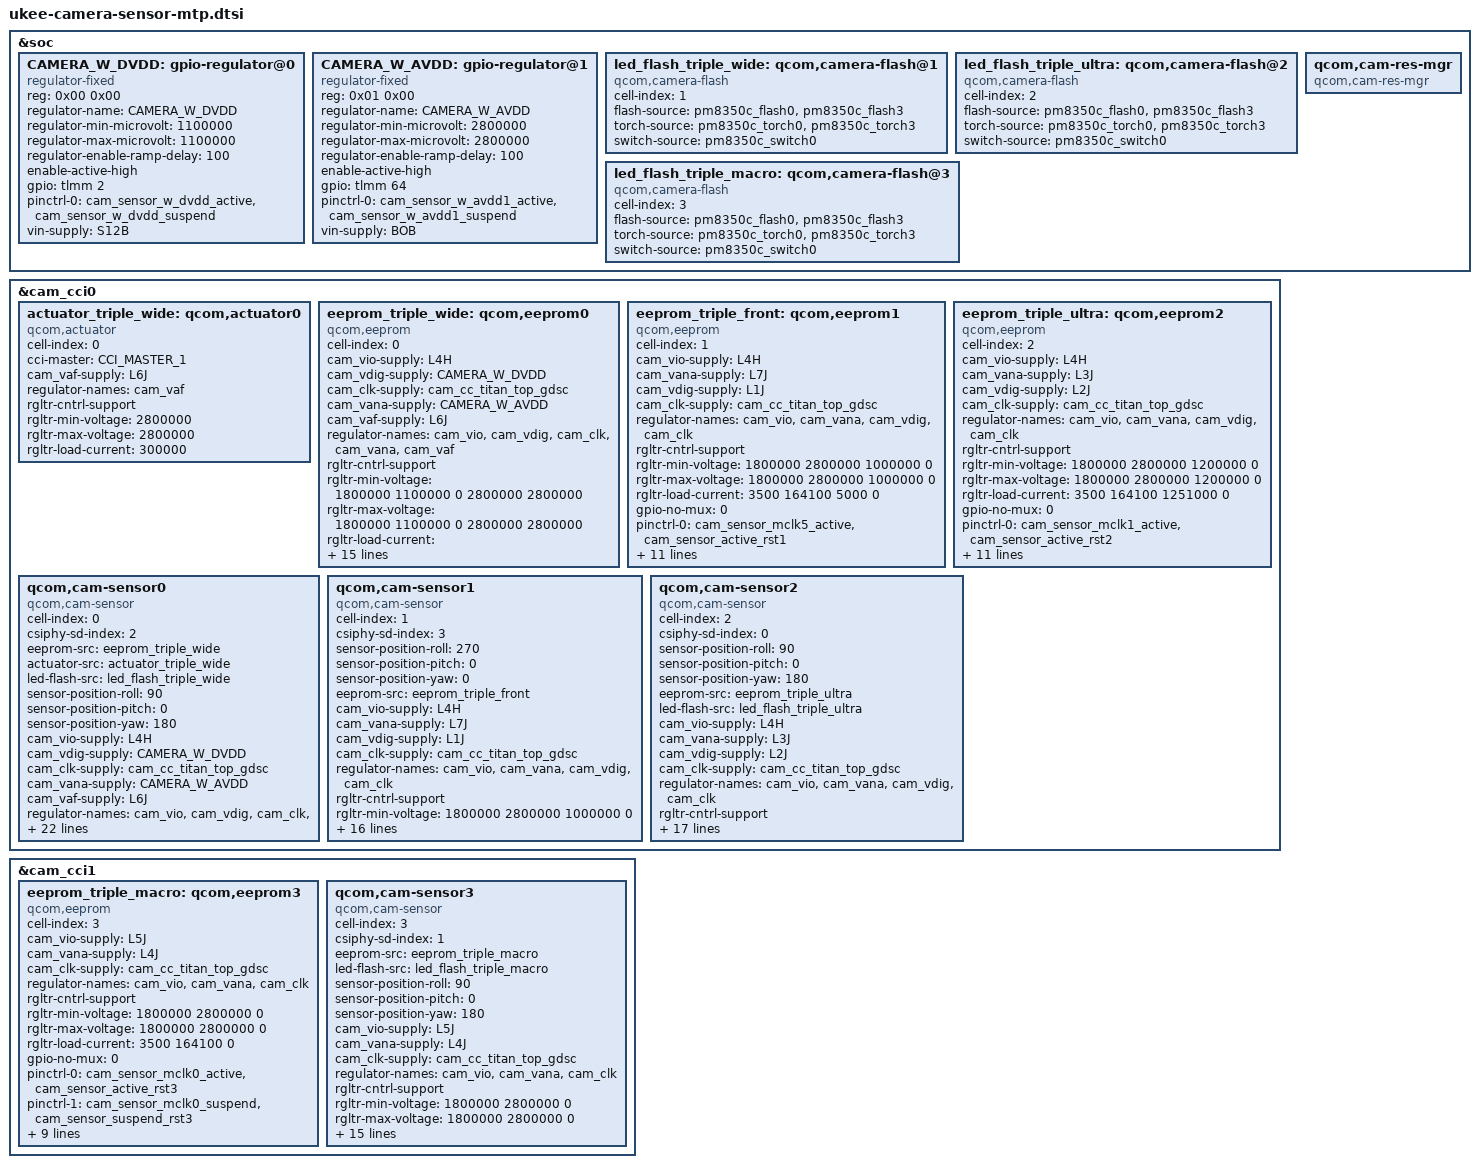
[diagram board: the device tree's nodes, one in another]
#include <dt-bindings/clock/qcom,camcc-waipio.h>
#include <dt-bindings/msm-camera.h>

&soc {
	CAMERA_W_DVDD: gpio-regulator@0 {
		compatible = "regulator-fixed";
		reg = <0x00 0x00>;
		regulator-name = "CAMERA_W_DVDD";
		regulator-min-microvolt = <1100000>;
		regulator-max-microvolt = <1100000>;
		regulator-enable-ramp-delay = <100>;
		enable-active-high;
		gpio = <&tlmm 2 0>;
		pinctrl-names = "default", "sleep";
		pinctrl-0 = <&cam_sensor_w_dvdd_active
			&cam_sensor_w_dvdd_suspend>;
		vin-supply = <&S12B>;
	};

	CAMERA_W_AVDD: gpio-regulator@1 {
		compatible = "regulator-fixed";
		reg = <0x01 0x00>;
		regulator-name = "CAMERA_W_AVDD";
		regulator-min-microvolt = <2800000>;
		regulator-max-microvolt = <2800000>;
		regulator-enable-ramp-delay = <100>;
		enable-active-high;
		gpio = <&tlmm 64 0>;
		pinctrl-names = "default", "sleep";
		pinctrl-0 = <&cam_sensor_w_avdd1_active
			&cam_sensor_w_avdd1_suspend>;
		vin-supply = <&BOB>;
	};

	led_flash_triple_wide: qcom,camera-flash@1 {
		cell-index = <1>;
		compatible = "qcom,camera-flash";
		flash-source = <&pm8350c_flash0 &pm8350c_flash3>;
		torch-source = <&pm8350c_torch0 &pm8350c_torch3>;
		switch-source = <&pm8350c_switch0>;
		status = "ok";
	};

	led_flash_triple_ultra: qcom,camera-flash@2 {
		cell-index = <2>;
		compatible = "qcom,camera-flash";
		flash-source = <&pm8350c_flash0 &pm8350c_flash3>;
		torch-source = <&pm8350c_torch0 &pm8350c_torch3>;
		switch-source = <&pm8350c_switch0>;
		status = "ok";
	};

	led_flash_triple_macro: qcom,camera-flash@3 {
		cell-index = <3>;
		compatible = "qcom,camera-flash";
		flash-source = <&pm8350c_flash0 &pm8350c_flash3>;
		torch-source = <&pm8350c_torch0 &pm8350c_torch3>;
		switch-source = <&pm8350c_switch0>;
		status = "ok";
	};

	qcom,cam-res-mgr {
		compatible = "qcom,cam-res-mgr";
		status = "ok";
	};
};

&cam_cci0 {
	actuator_triple_wide: qcom,actuator0 {
		cell-index = <0>;
		compatible = "qcom,actuator";
		cci-master = <CCI_MASTER_1>;
		cam_vaf-supply = <&L6J>;
		regulator-names = "cam_vaf";
		rgltr-cntrl-support;
		rgltr-min-voltage = <2800000>;
		rgltr-max-voltage = <2800000>;
		rgltr-load-current = <300000>;
		status = "ok";
	};

	eeprom_triple_wide: qcom,eeprom0 {
		cell-index = <0>;
		compatible = "qcom,eeprom";
		cam_vio-supply = <&L4H>;
		cam_vdig-supply = <&CAMERA_W_DVDD>;
		cam_clk-supply = <&cam_cc_titan_top_gdsc>;
		cam_vana-supply = <&CAMERA_W_AVDD>;
		cam_vaf-supply = <&L6J>;
		regulator-names = "cam_vio", "cam_vdig",
			"cam_clk", "cam_vana", "cam_vaf";
		rgltr-cntrl-support;
		rgltr-min-voltage = <1800000 1100000 0 2800000 2800000>;
		rgltr-max-voltage = <1800000 1100000 0 2800000 2800000>;
		rgltr-load-current = <3500 1251000 0 164100 300000>;
		gpio-no-mux = <0>;
		pinctrl-names = "cam_default", "cam_suspend";
		pinctrl-0 = <&cam_sensor_mclk2_active
			&cam_sensor_active_rst0>;
		pinctrl-1 = <&cam_sensor_mclk2_suspend
			&cam_sensor_suspend_rst0>;
		gpios = <&tlmm 102 0>,
			<&tlmm 126 0>;
		gpio-reset = <1>;
		gpio-req-tbl-num = <0 1>;
		gpio-req-tbl-flags = <1 0>;
		gpio-req-tbl-label = "CAMIF_MCLK2",
					"CAM_RESET0";
		cci-master = <CCI_MASTER_1>;
		clocks = <&clock_camcc CAM_CC_MCLK2_CLK>;
		clock-names = "cam_clk";
		clock-cntl-level = "nominal";
		clock-rates = <19200000>;
		status = "ok";
	};

	eeprom_triple_front: qcom,eeprom1 {
		cell-index = <1>;
		compatible = "qcom,eeprom";
		cam_vio-supply = <&L4H>;
		cam_vana-supply = <&L7J>;
		cam_vdig-supply = <&L1J>;
		cam_clk-supply = <&cam_cc_titan_top_gdsc>;
		regulator-names = "cam_vio", "cam_vana", "cam_vdig",
			"cam_clk";
		rgltr-cntrl-support;
		rgltr-min-voltage = <1800000 2800000 1000000 0>;
		rgltr-max-voltage = <1800000 2800000 1000000 0>;
		rgltr-load-current = <3500 164100 5000 0>;
		gpio-no-mux = <0>;
		pinctrl-names = "cam_default", "cam_suspend";
		pinctrl-0 = <&cam_sensor_mclk5_active
			&cam_sensor_active_rst1>;
		pinctrl-1 = <&cam_sensor_mclk5_suspend
			&cam_sensor_suspend_rst1>;
		gpios = <&tlmm 105 0>,
			<&tlmm 127 0>;
		gpio-reset = <1>;
		gpio-req-tbl-num = <0 1>;
		gpio-req-tbl-flags = <1 0>;
		gpio-req-tbl-label = "CAMIF_MCLK5",
					"CAM_RESET1";
		cci-master = <CCI_MASTER_0>;
		clocks = <&clock_camcc CAM_CC_MCLK5_CLK>;
		clock-names = "cam_clk";
		clock-cntl-level = "nominal";
		clock-rates = <19200000>;
		status = "ok";
	};

	eeprom_triple_ultra: qcom,eeprom2 {
		cell-index = <2>;
		compatible = "qcom,eeprom";
		cam_vio-supply = <&L4H>;
		cam_vana-supply = <&L3J>;
		cam_vdig-supply = <&L2J>;
		cam_clk-supply = <&cam_cc_titan_top_gdsc>;
		regulator-names = "cam_vio", "cam_vana", "cam_vdig",
			"cam_clk";
		rgltr-cntrl-support;
		rgltr-min-voltage = <1800000 2800000 1200000 0>;
		rgltr-max-voltage = <1800000 2800000 1200000 0>;
		rgltr-load-current = <3500 164100 1251000 0>;
		gpio-no-mux = <0>;
		pinctrl-names = "cam_default", "cam_suspend";
		pinctrl-0 = <&cam_sensor_mclk1_active
				 &cam_sensor_active_rst2>;
		pinctrl-1 = <&cam_sensor_mclk1_suspend
				 &cam_sensor_suspend_rst2>;
		gpios = <&tlmm 101 0>,
			<&tlmm 24 0>;
		gpio-reset = <1>;
		gpio-req-tbl-num = <0 1>;
		gpio-req-tbl-flags = <1 0>;
		gpio-req-tbl-label = "CAMIF_MCLK1",
					"CAM_RESET2";
		cci-master = <CCI_MASTER_0>;
		clocks = <&clock_camcc CAM_CC_MCLK1_CLK>;
		clock-names = "cam_clk";
		clock-cntl-level = "nominal";
		clock-rates = <19200000>;
		status = "ok";
	};

	qcom,cam-sensor0 {
		cell-index = <0>;
		compatible = "qcom,cam-sensor";
		csiphy-sd-index = <2>;
		eeprom-src = <&eeprom_triple_wide>;
		actuator-src = <&actuator_triple_wide>;
		led-flash-src = <&led_flash_triple_wide>;
		sensor-position-roll = <90>;
		sensor-position-pitch = <0>;
		sensor-position-yaw = <180>;
		cam_vio-supply = <&L4H>;
		cam_vdig-supply = <&CAMERA_W_DVDD>;
		cam_clk-supply = <&cam_cc_titan_top_gdsc>;
		cam_vana-supply = <&CAMERA_W_AVDD>;
		cam_vaf-supply = <&L6J>;
		regulator-names = "cam_vio", "cam_vdig",
			"cam_clk", "cam_vana", "cam_vaf";
		rgltr-cntrl-support;
		rgltr-min-voltage = <1800000 1100000 0 2800000 2800000>;
		rgltr-max-voltage = <1800000 1100000 0 2800000 2800000>;
		rgltr-load-current = <3500 164100 0 0x28104 300000>;
		gpio-no-mux = <0>;
		pinctrl-names = "cam_default", "cam_suspend";
		pinctrl-0 = <&cam_sensor_mclk2_active
			&cam_sensor_active_rst0>;
		pinctrl-1 = <&cam_sensor_mclk2_suspend
			&cam_sensor_suspend_rst0>;
		gpios = <&tlmm 102 0>,
			<&tlmm 126 0>;
		gpio-reset = <1>;
		gpio-req-tbl-num = <0 1>;
		gpio-req-tbl-flags = <1 0>;
		gpio-req-tbl-label = "CAMIF_MCLK2",
					"CAM_RESET0";
		cci-master = <CCI_MASTER_1>;
		clocks = <&clock_camcc CAM_CC_MCLK2_CLK>;
		clock-names = "cam_clk";
		clock-cntl-level = "nominal";
		clock-rates = <19200000>;
		status = "ok";
	};

	qcom,cam-sensor1 {
		cell-index = <1>;
		compatible = "qcom,cam-sensor";
		csiphy-sd-index = <3>;
		sensor-position-roll = <270>;
		sensor-position-pitch = <0>;
		sensor-position-yaw = <0>;
		eeprom-src = <&eeprom_triple_front>;
		cam_vio-supply = <&L4H>;
		cam_vana-supply = <&L7J>;
		cam_vdig-supply = <&L1J>;
		cam_clk-supply = <&cam_cc_titan_top_gdsc>;
		regulator-names = "cam_vio", "cam_vana", "cam_vdig",
			"cam_clk";
		rgltr-cntrl-support;
		rgltr-min-voltage = <1800000 2800000 1000000 0>;
		rgltr-max-voltage = <1800000 2800000 1000000 0>;
		rgltr-load-current = <3500 164100 5000 0>;
		gpio-no-mux = <0>;
		pinctrl-names = "cam_default", "cam_suspend";
		pinctrl-0 = <&cam_sensor_mclk5_active
				 &cam_sensor_active_rst1>;
		pinctrl-1 = <&cam_sensor_mclk5_suspend
				 &cam_sensor_suspend_rst1>;
		gpios = <&tlmm 105 0>,
			<&tlmm 127 0>;
		gpio-reset = <1>;
		gpio-req-tbl-num = <0 1>;
		gpio-req-tbl-flags = <1 0>;
		gpio-req-tbl-label = "CAMIF_MCLK5",
					"CAM_RESET1";
		cci-master = <CCI_MASTER_0>;
		clocks = <&clock_camcc CAM_CC_MCLK5_CLK>;
		clock-names = "cam_clk";
		clock-cntl-level = "nominal";
		clock-rates = <19200000>;
		status = "ok";
	};

	qcom,cam-sensor2 {
		cell-index = <2>;
		compatible = "qcom,cam-sensor";
		csiphy-sd-index = <0>;
		sensor-position-roll = <90>;
		sensor-position-pitch = <0>;
		sensor-position-yaw = <180>;
		eeprom-src = <&eeprom_triple_ultra>;
		led-flash-src = <&led_flash_triple_ultra>;
		cam_vio-supply = <&L4H>;
		cam_vana-supply = <&L3J>;
		cam_vdig-supply = <&L2J>;
		cam_clk-supply = <&cam_cc_titan_top_gdsc>;
		regulator-names = "cam_vio", "cam_vana", "cam_vdig",
			"cam_clk";
		rgltr-cntrl-support;
		rgltr-min-voltage = <1800000 2800000 1200000 0>;
		rgltr-max-voltage = <1800000 2800000 1200000 0>;
		rgltr-load-current = <3500 164100 1251000 0>;
		gpio-no-mux = <0>;
		pinctrl-names = "cam_default", "cam_suspend";
		pinctrl-0 = <&cam_sensor_mclk1_active
			&cam_sensor_active_rst2>;
		pinctrl-1 = <&cam_sensor_mclk1_suspend
			&cam_sensor_suspend_rst2>;
		gpios = <&tlmm 101 0>,
			<&tlmm 24 0>;
		gpio-reset = <1>;
		gpio-req-tbl-num = <0 1>;
		gpio-req-tbl-flags = <1 0>;
		gpio-req-tbl-label = "CAMIF_MCLK1",
					"CAM_RESET2";
		cci-master = <CCI_MASTER_0>;
		clocks = <&clock_camcc CAM_CC_MCLK1_CLK>;
		clock-names = "cam_clk";
		clock-cntl-level = "nominal";
		clock-rates = <19200000>;
		status = "ok";
	};
};

&cam_cci1 {
	eeprom_triple_macro: qcom,eeprom3 {
		cell-index = <3>;
		compatible = "qcom,eeprom";
		cam_vio-supply = <&L5J>;
		cam_vana-supply = <&L4J>;
		cam_clk-supply = <&cam_cc_titan_top_gdsc>;
		regulator-names = "cam_vio", "cam_vana",
			"cam_clk";
		rgltr-cntrl-support;
		rgltr-min-voltage = <1800000 2800000 0>;
		rgltr-max-voltage = <1800000 2800000 0>;
		rgltr-load-current = <3500 164100 0>;
		gpio-no-mux = <0>;
		pinctrl-names = "cam_default", "cam_suspend";
		pinctrl-0 = <&cam_sensor_mclk0_active
			&cam_sensor_active_rst3>;
		pinctrl-1 = <&cam_sensor_mclk0_suspend
			&cam_sensor_suspend_rst3>;
		gpios = <&tlmm 100 0>,
			<&tlmm 128 0>;
		gpio-reset = <1>;
		gpio-req-tbl-num = <0 1>;
		gpio-req-tbl-flags = <1 0>;
		gpio-req-tbl-label = "CAMIF_MCLK0",
					"CAM_RESET3";
		cci-master = <CCI_MASTER_0>;
		clocks = <&clock_camcc CAM_CC_MCLK0_CLK>;
		clock-names = "cam_clk";
		clock-cntl-level = "nominal";
		clock-rates = <19200000>;
		status = "ok";
	};

	qcom,cam-sensor3 {
		cell-index = <3>;
		compatible = "qcom,cam-sensor";
		csiphy-sd-index = <1>;
		eeprom-src = <&eeprom_triple_macro>;
		led-flash-src = <&led_flash_triple_macro>;
		sensor-position-roll = <90>;
		sensor-position-pitch = <0>;
		sensor-position-yaw = <180>;
		cam_vio-supply = <&L5J>;
		cam_vana-supply = <&L4J>;
		cam_clk-supply = <&cam_cc_titan_top_gdsc>;
		regulator-names = "cam_vio", "cam_vana",
			"cam_clk";
		rgltr-cntrl-support;
		rgltr-min-voltage = <1800000 2800000 0>;
		rgltr-max-voltage = <1800000 2800000 0>;
		rgltr-load-current = <3500 164100 0>;
		gpio-no-mux = <0>;
		pinctrl-names = "cam_default", "cam_suspend";
		pinctrl-0 = <&cam_sensor_mclk0_active
			&cam_sensor_active_rst3>;
		pinctrl-1 = <&cam_sensor_mclk0_suspend
			&cam_sensor_suspend_rst3>;
		gpios = <&tlmm 100 0>,
			<&tlmm 128 0>;
		gpio-reset = <1>;
		gpio-req-tbl-num = <0 1>;
		gpio-req-tbl-flags = <1 0>;
		gpio-req-tbl-label = "CAMIF_MCLK0",
					"CAM_RESET3";
		cci-master = <CCI_MASTER_0>;
		clocks = <&clock_camcc CAM_CC_MCLK0_CLK>;
		clock-names = "cam_clk";
		clock-cntl-level = "nominal";
		clock-rates = <19200000>;
		status = "ok";
	};
};
